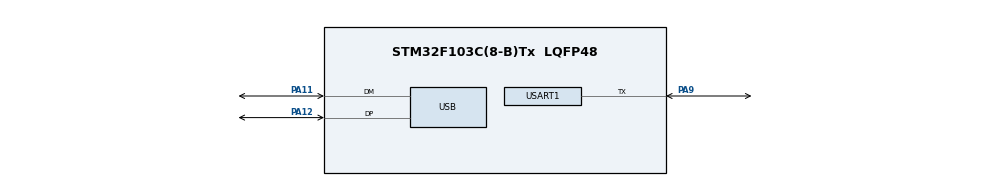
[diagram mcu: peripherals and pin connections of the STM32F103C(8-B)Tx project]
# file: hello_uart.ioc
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Mcu.Family=STM32F1
Mcu.Name=STM32F103C(8-B)Tx
Mcu.Package=LQFP48
NVIC.PriorityGroup=NVIC_PRIORITYGROUP_4
PA11.Mode=Device
PA11.Signal=USB_DM
PA12.Mode=Device
PA12.Signal=USB_DP
PA13.Mode=Serial_Wire
PA13.Signal=SYS_JTMS-SWDIO
PA14.Mode=Serial_Wire
PA14.Signal=SYS_JTCK-SWCLK
PA9.Mode=Half_duplex(single_wire_mode)
PA9.Signal=USART1_TX
PD0-OSC_IN.Mode=HSE-External-Oscillator
PD0-OSC_IN.Signal=RCC_OSC_IN
PD1-OSC_OUT.Mode=HSE-External-Oscillator
PD1-OSC_OUT.Signal=RCC_OSC_OUT
ProjectManager.HeapSize=0x200
ProjectManager.StackSize=0x400
ProjectManager.TargetToolchain=STM32CubeIDE
RCC.APB1Freq_Value=8000000
RCC.APB2Freq_Value=8000000
RCC.PLLSourceVirtualString=RCC_PLLSOURCE_HSI_DIV2
USART1.VirtualMode=VM_ASYNC
board=custom

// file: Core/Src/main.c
/* USER CODE BEGIN Header */
/**
  ******************************************************************************
  * @file           : main.c
  * @brief          : Main program body
  ******************************************************************************
  * @attention
  *
  * Copyright (c) 2024 STMicroelectronics.
  * All rights reserved.
  *
  * This software is licensed under terms that can be found in the LICENSE file
  * in the root directory of this software component.
  * If no LICENSE file comes with this software, it is provided AS-IS.
  *
  ******************************************************************************
  */
/* USER CODE END Header */
#include "main.h"

/* USER CODE BEGIN Includes */
#include <string.h>
/* USER CODE END Includes */

UART_HandleTypeDef huart1;

PCD_HandleTypeDef hpcd_USB_FS;

/* USER CODE BEGIN PV */
static const char helloMsg[] = "Hello World\r\n";
/* USER CODE END PV */

void SystemClock_Config(void);
static void MX_GPIO_Init(void);
static void MX_USART1_UART_Init(void);
static void MX_USB_PCD_Init(void);
/* USER CODE BEGIN PFP */
static void sendMessage(const char *message);
/* USER CODE END PFP */

int main(void)
{

  /* MCU Configuration--------------------------------------------------------*/

  /* Reset of all peripherals, Initializes the Flash interface and the Systick. */
  HAL_Init();

  /* Configure the system clock */
  SystemClock_Config();

  /* Initialize all configured peripherals */
  MX_GPIO_Init();
  MX_USART1_UART_Init();
  MX_USB_PCD_Init();

  /* Infinite loop */
  /* USER CODE BEGIN WHILE */
  while (1)
  {
    sendMessage(helloMsg);
    HAL_Delay(1000);
    /* USER CODE END WHILE */

  }
}

void SystemClock_Config(void)
{
  RCC_OscInitTypeDef RCC_OscInitStruct = {0};
  RCC_ClkInitTypeDef RCC_ClkInitStruct = {0};
  RCC_PeriphCLKInitTypeDef PeriphClkInit = {0};

  /** Initializes the RCC Oscillators according to the specified parameters
  * in the RCC_OscInitTypeDef structure.
  */
  RCC_OscInitStruct.OscillatorType = RCC_OSCILLATORTYPE_HSI;
  RCC_OscInitStruct.HSIState = RCC_HSI_ON;
  RCC_OscInitStruct.HSICalibrationValue = RCC_HSICALIBRATION_DEFAULT;
  RCC_OscInitStruct.PLL.PLLState = RCC_PLL_ON;
  RCC_OscInitStruct.PLL.PLLSource = RCC_PLLSOURCE_HSI_DIV2;
  RCC_OscInitStruct.PLL.PLLMUL = RCC_PLL_MUL2;
  if (HAL_RCC_OscConfig(&RCC_OscInitStruct) != HAL_OK)
  {
    Error_Handler();
  }

  /** Initializes the CPU, AHB and APB buses clocks
  */
  RCC_ClkInitStruct.ClockType = RCC_CLOCKTYPE_HCLK|RCC_CLOCKTYPE_SYSCLK
                              |RCC_CLOCKTYPE_PCLK1|RCC_CLOCKTYPE_PCLK2;
  RCC_ClkInitStruct.SYSCLKSource = RCC_SYSCLKSOURCE_HSI;
  RCC_ClkInitStruct.AHBCLKDivider = RCC_SYSCLK_DIV1;
  RCC_ClkInitStruct.APB1CLKDivider = RCC_HCLK_DIV1;
  RCC_ClkInitStruct.APB2CLKDivider = RCC_HCLK_DIV1;

  if (HAL_RCC_ClockConfig(&RCC_ClkInitStruct, FLASH_LATENCY_0) != HAL_OK)
  {
    Error_Handler();
  }
  PeriphClkInit.PeriphClockSelection = RCC_PERIPHCLK_USB;
  PeriphClkInit.UsbClockSelection = RCC_USBCLKSOURCE_PLL;
  if (HAL_RCCEx_PeriphCLKConfig(&PeriphClkInit) != HAL_OK)
  {
    Error_Handler();
  }
}

static void MX_USART1_UART_Init(void)
{

  huart1.Instance = USART1;
  huart1.Init.BaudRate = 115200;
  huart1.Init.WordLength = UART_WORDLENGTH_8B;
  huart1.Init.StopBits = UART_STOPBITS_1;
  huart1.Init.Parity = UART_PARITY_NONE;
  huart1.Init.Mode = UART_MODE_TX_RX;
  huart1.Init.HwFlowCtl = UART_HWCONTROL_NONE;
  huart1.Init.OverSampling = UART_OVERSAMPLING_16;
  if (HAL_HalfDuplex_Init(&huart1) != HAL_OK)
  {
    Error_Handler();
  }

}

static void MX_USB_PCD_Init(void)
{

  hpcd_USB_FS.Instance = USB;
  hpcd_USB_FS.Init.dev_endpoints = 8;
  hpcd_USB_FS.Init.speed = PCD_SPEED_FULL;
  hpcd_USB_FS.Init.low_power_enable = DISABLE;
  hpcd_USB_FS.Init.lpm_enable = DISABLE;
  hpcd_USB_FS.Init.battery_charging_enable = DISABLE;
  if (HAL_PCD_Init(&hpcd_USB_FS) != HAL_OK)
  {
    Error_Handler();
  }

}

static void MX_GPIO_Init(void)
{

  /* GPIO Ports Clock Enable */
  __HAL_RCC_GPIOD_CLK_ENABLE();
  __HAL_RCC_GPIOA_CLK_ENABLE();

}

/* USER CODE BEGIN 4 */
static void sendMessage(const char *message)
{
  HAL_UART_Transmit(&huart1, (const uint8_t *)message, (uint16_t)strlen(message), HAL_MAX_DELAY);
}
/* USER CODE END 4 */

void Error_Handler(void)
{
  __disable_irq();
  while (1)
  {
  }
}
